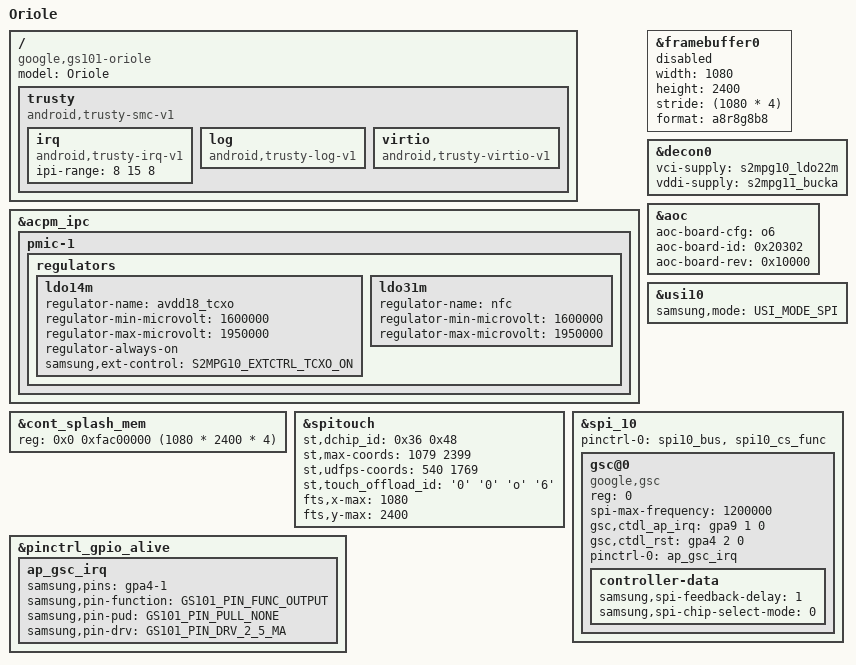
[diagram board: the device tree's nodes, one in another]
// SPDX-License-Identifier: GPL-2.0-only
/*
 * Oriole Device Tree
 *
 * Copyright 2021-2023 Google LLC
 * Copyright 2023 Linaro Ltd - <peter.griffin@linaro.org>
 */

/dts-v1/;

#include <dt-bindings/regulator/samsung,s2mpg10-regulator.h>
#include "gs101-pixel-common.dtsi"

/ {
	model = "Oriole";
	compatible = "google,gs101-oriole", "google,gs101";
};

&acpm_ipc {
	pmic-1 {
		regulators {
			ldo14m {
				/* PLL */
				regulator-name = "avdd18_tcxo";
				regulator-min-microvolt = <1600000>;
				regulator-max-microvolt = <1950000>;
				regulator-always-on;
				samsung,ext-control = <S2MPG10_EXTCTRL_TCXO_ON>;
			};

			ldo31m {
				regulator-name = "nfc";
				regulator-min-microvolt = <1600000>;
				regulator-max-microvolt = <1950000>;
			};
		};
	};
};

&cont_splash_mem {
	reg = <0x0 0xfac00000 (1080 * 2400 * 4)>;
	status = "okay";
};

/*
 * Left disabled: gs101_drm drives this panel now, and a second driver on the
 * same memory made every display measurement ambiguous -- which card modetest
 * opened, which framebuffer the picture came from. The properties stay so the
 * node can be turned back on with one word if the DRM driver is ever out of
 * action. Note that raven and bluejay still enable theirs.
 */
&framebuffer0 {
	width = <1080>;
	height = <2400>;
	stride = <(1080 * 4)>;
	format = "a8r8g8b8";
	status = "disabled";
};

/*
 * The panel's supplies, the same two framebuffer0 holds. They are described
 * here rather than in gs101.dtsi because they are board-level.
 *
 * DECON has no business owning these -- they belong to the panel, and should
 * move to a panel node once DSIM exists. Until then something has to hold them
 * across the handover: taking the display over unbinds simpledrm, which drops
 * its references, and with no other user vci_disp is switched off and the
 * panel dies mid-frame. That is not recoverable without a reboot, because the
 * bootloader is what powers the panel back up.
 */
&decon0 {
	vci-supply = <&s2mpg10_ldo22m>;
	vddi-supply = <&s2mpg11_bucka>;
};

&spitouch {
	st,dchip_id = /bits/ 8 <0x36 0x48>;
	st,max-coords = <1079 2399>;
	st,udfps-coords = <540 1769>;
	st,touch_offload_id = /bits/ 8 <'0' '0' 'o' '6'>;

	fts,x-max = <1080>;
	fts,y-max = <2400>;
};

&aoc {
	aoc-board-cfg = "o6";
	aoc-board-id = <0x20302>;
	aoc-board-rev = <0x10000>;
};

/*
 * Trusty (secure world) — stock Trusty is resident behind ABL and answers
 * SMCs (trusty_probe: api v5, "Project: slider"). Normal-world SMC transport
 * node so the ported google-modules/trusty driver can reach it.
 */
/ {
	trusty: trusty {
		compatible = "android,trusty-smc-v1";

		irq {
			compatible = "android,trusty-irq-v1";
			ipi-range = <8 15 8>;
		};

		log {
			compatible = "android,trusty-log-v1";
		};

		virtio {
			compatible = "android,trusty-virtio-v1";
		};
	};
};

/*
 * GSC / Titan-M2 (google,gsc) on spi_10. Ported google-modules gsc-spi driver
 * (creates /dev/gsc0 for libnos/citadel_updater: TPM datagram + GSA nos-call).
 * Titan-M2 = Nugget OS on RISC-V (Ibex). Reset/IRQ via Citadel GPIOs (ctdl_*).
 */
&pinctrl_gpio_alive {
	ap_gsc_irq: ap_gsc_irq {
		samsung,pins = "gpa4-1";
		samsung,pin-function = <GS101_PIN_FUNC_OUTPUT>;
		samsung,pin-pud = <GS101_PIN_PULL_NONE>;
		samsung,pin-drv = <GS101_PIN_DRV_2_5_MA>;
	};
};

&usi10 {
	samsung,mode = <USI_MODE_SPI>;
	status = "okay";
};

&spi_10 {
	status = "okay";
	#address-cells = <1>;
	#size-cells = <0>;
	pinctrl-names = "default";
	pinctrl-0 = <&spi10_bus &spi10_cs_func>;

	gsc@0 {
		compatible = "google,gsc";
		reg = <0>;
		spi-max-frequency = <1200000>;
		gsc,ctdl_ap_irq = <&gpa9 1 0>;
		gsc,ctdl_rst = <&gpa4 2 0>;
		pinctrl-names = "default";
		pinctrl-0 = <&ap_gsc_irq>;
		controller-data {
			samsung,spi-feedback-delay = <1>;
			samsung,spi-chip-select-mode = <0>;
		};
	};
};
